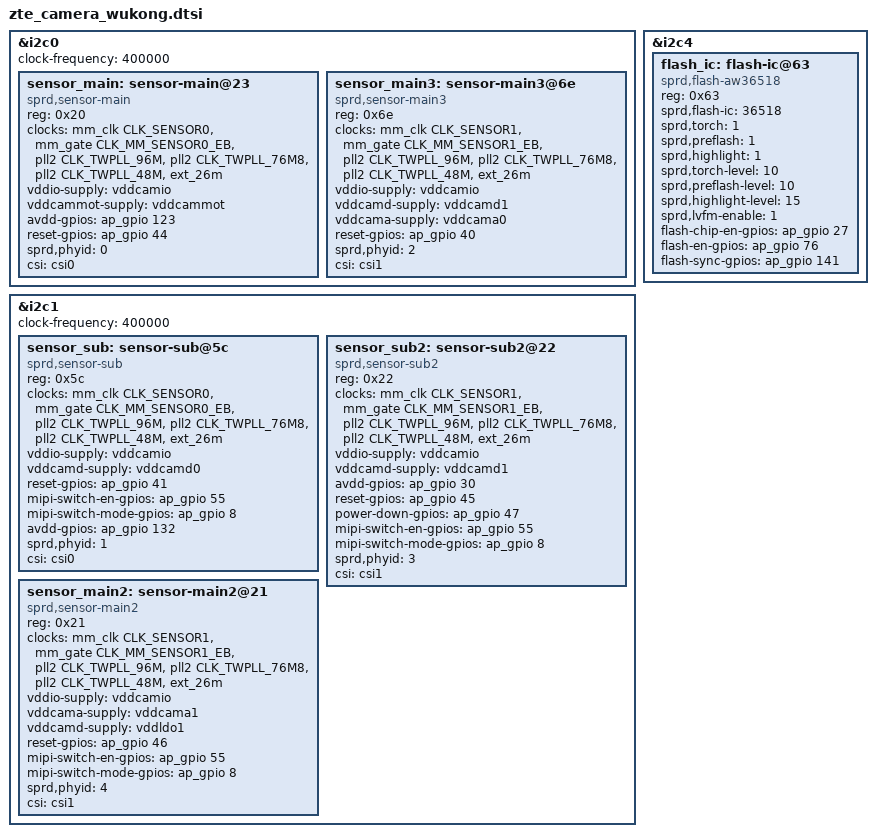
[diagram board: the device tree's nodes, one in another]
&i2c0 {
	/delete-node/ sensor-main@20;
};

&i2c0 {
	/delete-node/ sensor-sub@5a;
};

&i2c1 {
	/delete-node/ sensor-sub2@6e;
};

&i2c1 {
	/delete-node/ sensor-main2@20;
};

&i2c1 {
	/delete-node/ sensor-main3@6c;
};

&i2c0 {
	status = "okay";
	clock-frequency = <400000>;

	// main camera: OV64B40 64M
	sensor_main: sensor-main@23 {
		compatible = "sprd,sensor-main";
		reg = <0x20>;
		clock-names = "clk_src","sensor_eb",
			"clk_96m","clk_76m8",
			"clk_48m","clk_26m";
		clocks = <&mm_clk CLK_SENSOR0>,<&mm_gate CLK_MM_SENSOR0_EB>,
				<&pll2 CLK_TWPLL_96M>,<&pll2 CLK_TWPLL_76M8>,
				<&pll2 CLK_TWPLL_48M>,<&ext_26m>;
		vddio-supply = <&vddcamio>;
		//vddcama-supply = <&vddcama>;
		//vddcamd-supply = <&vddcamd>;
		vddcammot-supply = <&vddcammot>;

		avdd-gpios=<&ap_gpio 123 0>;
		reset-gpios = <&ap_gpio 44 0>;
		sprd,phyid = <0>;
		csi = <&csi0>;
	};

	//macro: GC5035 5M
	sensor_main3: sensor-main3@6e {
		compatible = "sprd,sensor-main3";
		reg = <0x6e>;
		clock-names = "clk_src","sensor_eb",
			"clk_96m","clk_76m8",
			"clk_48m","clk_26m";
		clocks = <&mm_clk CLK_SENSOR1>,<&mm_gate CLK_MM_SENSOR1_EB>,
			<&pll2 CLK_TWPLL_96M>,<&pll2 CLK_TWPLL_76M8>,
			<&pll2 CLK_TWPLL_48M>,<&ext_26m>;
		vddio-supply = <&vddcamio>;
		vddcamd-supply = <&vddcamd1>;
		vddcama-supply = <&vddcama0>;
		reset-gpios = <&ap_gpio 40 0>;
		sprd,phyid = <2>;
		csi = <&csi1>;
	};
};

&i2c1 {
	status = "okay";
	clock-frequency = <400000>;

	// front camera: OV16A1Q 16M
	sensor_sub: sensor-sub@5c {
		compatible = "sprd,sensor-sub";
		reg = <0x5c>;
		clock-names = "clk_src","sensor_eb",
			"clk_96m","clk_76m8",
			"clk_48m","clk_26m";
		clocks = <&mm_clk CLK_SENSOR0>,<&mm_gate CLK_MM_SENSOR0_EB>,
				<&pll2 CLK_TWPLL_96M>,<&pll2 CLK_TWPLL_76M8>,
				<&pll2 CLK_TWPLL_48M>,<&ext_26m>;

		vddio-supply = <&vddcamio>;
		vddcamd-supply = <&vddcamd0>;
		reset-gpios = <&ap_gpio 41 0>;
		//power-down-gpios = <&ap_gpio 46 0>;
		mipi-switch-en-gpios = <&ap_gpio 55 0>;
		mipi-switch-mode-gpios = <&ap_gpio 8 0>;
		avdd-gpios=<&ap_gpio 132 0>;
		sprd,phyid = <1>;
		csi = <&csi0>;
	};

	//UWIDE: HI846 8M
	sensor_sub2: sensor-sub2@22 {
		compatible = "sprd,sensor-sub2";
		reg = <0x22>;
		clock-names = "clk_src","sensor_eb",
			"clk_96m","clk_76m8",
			"clk_48m","clk_26m";
		clocks = <&mm_clk CLK_SENSOR1>,<&mm_gate CLK_MM_SENSOR1_EB>,
				<&pll2 CLK_TWPLL_96M>,<&pll2 CLK_TWPLL_76M8>,
				<&pll2 CLK_TWPLL_48M>,<&ext_26m>;
		vddio-supply = <&vddcamio>;
		vddcamd-supply = <&vddcamd1>;
		//vddcama-supply = <&vddcama>;
		avdd-gpios=<&ap_gpio 30 0>;
		reset-gpios = <&ap_gpio 45 0>;
		power-down-gpios = <&ap_gpio 47 0>;
		mipi-switch-en-gpios = <&ap_gpio 55 0>;
		mipi-switch-mode-gpios = <&ap_gpio 8 0>;
		sprd,phyid = <3>;
		csi = <&csi1>;
	};

	//DEPTH: GC02M1B 2M
	sensor_main2: sensor-main2@21 {
		compatible = "sprd,sensor-main2";
		reg = <0x21>;
		clock-names = "clk_src","sensor_eb",
			"clk_96m","clk_76m8",
			"clk_48m","clk_26m";
		clocks = <&mm_clk CLK_SENSOR1>,<&mm_gate CLK_MM_SENSOR1_EB>,
			<&pll2 CLK_TWPLL_96M>,<&pll2 CLK_TWPLL_76M8>,
			<&pll2 CLK_TWPLL_48M>,<&ext_26m>;
		vddio-supply = <&vddcamio>;
		vddcama-supply = <&vddcama1>;
		vddcamd-supply = <&vddldo1>;
		reset-gpios = <&ap_gpio 46 0>;
		mipi-switch-en-gpios = <&ap_gpio 55 0>;
		mipi-switch-mode-gpios = <&ap_gpio 8 0>;
		sprd,phyid = <4>;
		csi = <&csi1>;
	};
};
&i2c4 {
	/delete-node/ flash-ic@63;
};
&i2c4 {
	flash_ic: flash-ic@63 {
		compatible = "sprd,flash-aw36518";
		reg = <0x63>;
		sprd,flash-ic = <36518>;
		sprd,torch = <1>;
		sprd,preflash = <1>;
		sprd,highlight = <1>;
		sprd,torch-level = <10>;
		sprd,preflash-level = <10>;
		sprd,highlight-level = <15>;
		sprd,lvfm-enable = <1>;
		flash-chip-en-gpios = <&ap_gpio 27 0>;
		flash-en-gpios = <&ap_gpio 76 0>;
		flash-sync-gpios = <&ap_gpio 141 0>;
	};
};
